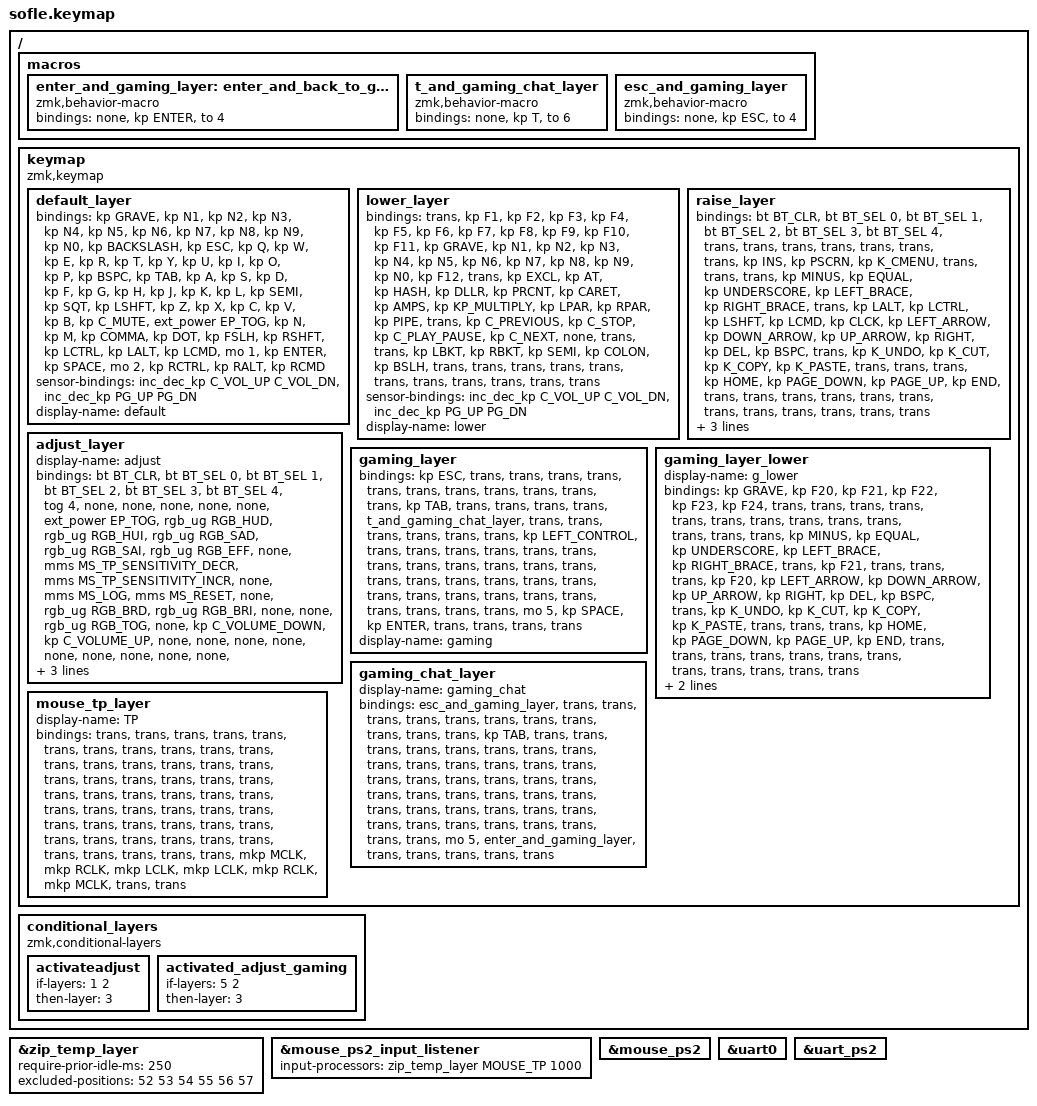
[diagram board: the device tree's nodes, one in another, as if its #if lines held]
/*
 * Copyright (c) 2020 The ZMK Contributors
 *
 * SPDX-License-Identifier: MIT
 */

#include <behaviors.dtsi>
#include <dt-bindings/zmk/bt.h>
#include <dt-bindings/zmk/ext_power.h>
#include <dt-bindings/zmk/keys.h>
#include <dt-bindings/zmk/rgb.h>
#include <dt-bindings/zmk/pointing.h>
#include <dt-bindings/zmk/mouse_settings.h>
#include <behaviors/mouse_setting.dtsi>
#include <input/processors.dtsi>

#define MOUSE_TP 7  // auto-activated by TrackPoint movement; must stay the highest layer

/ {
    macros {
        enter_and_gaming_layer: enter_and_back_to_gaming_layer {
            compatible = "zmk,behavior-macro";
            #binding-cells = <0>;
            bindings = <&none &kp ENTER &to 4>;
        };

        t_and_gaming_chat_layer: t_and_gaming_chat_layer {
            compatible = "zmk,behavior-macro";
            #binding-cells = <0>;
            bindings = <&none &kp T &to 6>;
        };

        esc_and_gaming_layer: esc_and_gaming_layer {
            compatible = "zmk,behavior-macro";
            #binding-cells = <0>;
            bindings = <&none &kp ESC &to 4>;
        };
    };

    keymap {
        compatible = "zmk,keymap";

        default_layer {
            bindings = <
&kp GRAVE  &kp N1  &kp N2     &kp N3    &kp N4    &kp N5                                   &kp N6  &kp N7     &kp N8     &kp N9    &kp N0    &kp BACKSLASH
&kp ESC    &kp Q   &kp W      &kp E     &kp R     &kp T                                    &kp Y   &kp U      &kp I      &kp O     &kp P     &kp BSPC
&kp TAB    &kp A   &kp S      &kp D     &kp F     &kp G                                    &kp H   &kp J      &kp K      &kp L     &kp SEMI  &kp SQT
&kp LSHFT  &kp Z   &kp X      &kp C     &kp V     &kp B   &kp C_MUTE    &ext_power EP_TOG  &kp N   &kp M      &kp COMMA  &kp DOT   &kp FSLH  &kp RSHFT
                   &kp LCTRL  &kp LALT  &kp LCMD  &mo 1   &kp ENTER     &kp SPACE          &mo 2   &kp RCTRL  &kp RALT   &kp RCMD
            >;

            sensor-bindings = <&inc_dec_kp C_VOL_UP C_VOL_DN &inc_dec_kp PG_UP PG_DN>;
            display-name = "default";
        };

        lower_layer {
            bindings = <
&trans     &kp F1          &kp F2      &kp F3            &kp F4      &kp F5                       &kp F6     &kp F7    &kp F8           &kp F9     &kp F10   &kp F11
&kp GRAVE  &kp N1          &kp N2      &kp N3            &kp N4      &kp N5                       &kp N6     &kp N7    &kp N8           &kp N9     &kp N0    &kp F12
&trans     &kp EXCL        &kp AT      &kp HASH          &kp DLLR    &kp PRCNT                    &kp CARET  &kp AMPS  &kp KP_MULTIPLY  &kp LPAR   &kp RPAR  &kp PIPE
&trans     &kp C_PREVIOUS  &kp C_STOP  &kp C_PLAY_PAUSE  &kp C_NEXT  &none      &trans    &trans  &kp LBKT   &kp RBKT  &kp SEMI         &kp COLON  &kp BSLH  &trans
                           &trans      &trans            &trans      &trans     &trans    &trans  &trans     &trans    &trans           &trans
            >;

            sensor-bindings = <&inc_dec_kp C_VOL_UP C_VOL_DN &inc_dec_kp PG_UP PG_DN>;
            display-name = "lower";
        };

        raise_layer {
            bindings = <
&bt BT_CLR  &bt BT_SEL 0  &bt BT_SEL 1  &bt BT_SEL 2  &bt BT_SEL 3  &bt BT_SEL 4                    &trans          &trans          &trans        &trans          &trans          &trans
&trans      &kp INS       &kp PSCRN     &kp K_CMENU   &trans        &trans                          &trans          &kp MINUS       &kp EQUAL     &kp UNDERSCORE  &kp LEFT_BRACE  &kp RIGHT_BRACE
&trans      &kp LALT      &kp LCTRL     &kp LSHFT     &kp LCMD      &kp CLCK                        &kp LEFT_ARROW  &kp DOWN_ARROW  &kp UP_ARROW  &kp RIGHT       &kp DEL         &kp BSPC
&trans      &kp K_UNDO    &kp K_CUT     &kp K_COPY    &kp K_PASTE   &trans        &trans    &trans  &kp HOME        &kp PAGE_DOWN   &kp PAGE_UP   &kp END         &trans          &trans
                          &trans        &trans        &trans        &trans        &trans    &trans  &trans          &trans          &trans        &trans
            >;

            sensor-bindings = <&inc_dec_kp C_VOL_UP C_VOL_DN &inc_dec_kp PG_UP PG_DN>;
            display-name = "raise";
        };

        adjust_layer {
            display-name = "adjust";
            bindings = <
&bt BT_CLR         &bt BT_SEL 0     &bt BT_SEL 1     &bt BT_SEL 2     &bt BT_SEL 3     &bt BT_SEL 4                               &tog 4  &none              &none            &none  &none  &none
&ext_power EP_TOG  &rgb_ug RGB_HUD  &rgb_ug RGB_HUI  &rgb_ug RGB_SAD  &rgb_ug RGB_SAI  &rgb_ug RGB_EFF                            &none   &mms MS_TP_SENSITIVITY_DECR  &mms MS_TP_SENSITIVITY_INCR  &none  &mms MS_LOG  &mms MS_RESET
&none              &rgb_ug RGB_BRD  &rgb_ug RGB_BRI  &none            &none            &rgb_ug RGB_TOG                            &none   &kp C_VOLUME_DOWN  &kp C_VOLUME_UP  &none  &none  &none
&none              &none            &none            &none            &none            &none            &rgb_ug RGB_TOG    &none  &none   &none              &none            &none  &none  &none
                                    &none            &none            &none            &none            &none              &none  &none   &none              &none            &none
            >;
        };

        gaming_layer {
            bindings = <
&kp ESC           &trans  &trans  &trans  &trans  &trans                                            &trans  &trans  &trans  &trans  &trans  &trans
&kp TAB           &trans  &trans  &trans  &trans  &t_and_gaming_chat_layer                          &trans  &trans  &trans  &trans  &trans  &trans
&kp LEFT_CONTROL  &trans  &trans  &trans  &trans  &trans                                            &trans  &trans  &trans  &trans  &trans  &trans
&trans            &trans  &trans  &trans  &trans  &trans                    &trans       &trans     &trans  &trans  &trans  &trans  &trans  &trans
                          &trans  &trans  &trans  &mo 5                     &kp SPACE    &kp ENTER  &trans  &trans  &trans  &trans
            >;

            display-name = "gaming";
        };

        gaming_layer_lower {
            display-name = "g_lower";
            bindings = <
&kp GRAVE  &kp F20     &kp F21    &kp F22     &kp F23      &kp F24                    &trans          &trans          &trans        &trans          &trans          &trans
&trans     &trans      &trans     &trans      &trans       &trans                     &trans          &kp MINUS       &kp EQUAL     &kp UNDERSCORE  &kp LEFT_BRACE  &kp RIGHT_BRACE
&trans     &kp F21     &trans     &trans      &trans       &kp F20                    &kp LEFT_ARROW  &kp DOWN_ARROW  &kp UP_ARROW  &kp RIGHT       &kp DEL         &kp BSPC
&trans     &kp K_UNDO  &kp K_CUT  &kp K_COPY  &kp K_PASTE  &trans   &trans    &trans  &kp HOME        &kp PAGE_DOWN   &kp PAGE_UP   &kp END         &trans          &trans
                       &trans     &trans      &trans       &trans   &trans    &trans  &trans          &trans          &trans        &trans
            >;

            sensor-bindings =
                <&inc_dec_kp C_VOL_UP C_VOL_DN>,
                <&inc_dec_kp PG_UP PG_DN>;
        };

        gaming_chat_layer {
            display-name = "gaming_chat";
            bindings = <
&esc_and_gaming_layer  &trans  &trans  &trans  &trans  &trans                                     &trans  &trans  &trans  &trans  &trans  &trans
&kp TAB                &trans  &trans  &trans  &trans  &trans                                     &trans  &trans  &trans  &trans  &trans  &trans
&trans                 &trans  &trans  &trans  &trans  &trans                                     &trans  &trans  &trans  &trans  &trans  &trans
&trans                 &trans  &trans  &trans  &trans  &trans  &trans                     &trans  &trans  &trans  &trans  &trans  &trans  &trans
                               &trans  &trans  &trans  &mo 5   &enter_and_gaming_layer    &trans  &trans  &trans  &trans  &trans
            >;
        };

        mouse_tp_layer {
            display-name = "TP";
            bindings = <
&trans  &trans  &trans  &trans  &trans  &trans                                      &trans        &trans  &trans  &trans  &trans  &trans
&trans  &trans  &trans  &trans  &trans  &trans                                      &trans        &trans  &trans  &trans  &trans  &trans
&trans  &trans  &trans  &trans  &trans  &trans                                      &trans        &trans  &trans  &trans  &trans  &trans
&trans  &trans  &trans  &trans  &trans  &trans  &trans                      &trans  &trans        &trans  &trans  &trans  &trans  &trans
                &trans  &trans  &mkp MCLK  &mkp RCLK  &mkp LCLK    &mkp LCLK  &mkp RCLK  &mkp MCLK  &trans  &trans
            >;
        };
    };

    conditional_layers {
        compatible = "zmk,conditional-layers";

        activateadjust {
            if-layers = <1 2>;
            then-layer = <3>;
        };

        activated_adjust_gaming {
            if-layers = <5 2>;
            then-layer = <3>;
        };
    };
};

#ifdef MOUSE_PS2_DT_PRESENT  // defined by sofle_right.overlay; absent on the left half
&zip_temp_layer {
    require-prior-idle-ms = <250>;                // no activation while typing
    excluded-positions = <52 53 54 55 56 57>;     // click keys; any other key exits the TP layer
};

&mouse_ps2_input_listener {
    status = "okay";
    input-processors = <&zip_temp_layer MOUSE_TP 1000>;  // TP layer stays 1 s after movement
};

&mouse_ps2 { status = "okay"; };
&uart0 { status = "okay"; };
&uart_ps2 { status = "okay"; };
#endif
